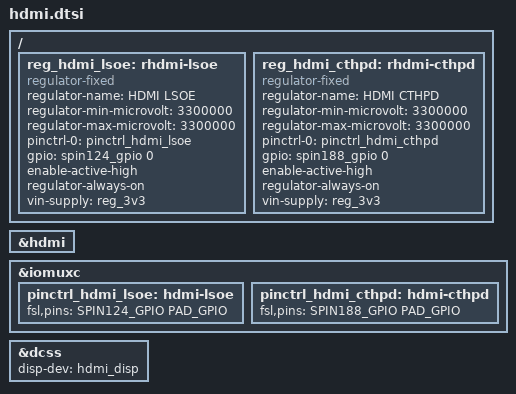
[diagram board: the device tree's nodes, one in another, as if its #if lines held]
/*
 * Copyright 2020 Keith & Koep GmbH
 *
 */

 /************************************************************************/

&hdmi {
	status = "okay";
};

&iomuxc {
	pinctrl_hdmi_lsoe: hdmi-lsoe 	{
		fsl,pins = < SPIN124_GPIO	PAD_GPIO >; 
	};
	pinctrl_hdmi_cthpd: hdmi-cthpd 	{
		fsl,pins = < SPIN188_GPIO	PAD_GPIO >; 
	};		
};

/ {
	reg_hdmi_lsoe: rhdmi-lsoe {
		compatible = "regulator-fixed";
		regulator-name = "HDMI LSOE";
		regulator-min-microvolt = <3300000>;
		regulator-max-microvolt = <3300000>;
		pinctrl-names = "default";
		pinctrl-0 = <&pinctrl_hdmi_lsoe>;
		gpio = <spin124_gpio 0>;
		enable-active-high;
		regulator-always-on;
		vin-supply = <&reg_3v3>;
	};
	reg_hdmi_cthpd: rhdmi-cthpd {
		compatible = "regulator-fixed";
		regulator-name = "HDMI CTHPD";
		regulator-min-microvolt = <3300000>;
		regulator-max-microvolt = <3300000>;
		pinctrl-names = "default";
		pinctrl-0 = <&pinctrl_hdmi_cthpd>;
		gpio = <spin188_gpio 0>;
		enable-active-high;
		regulator-always-on;
		vin-supply = <&reg_3v3>;
	};
};

#if defined (__DTS_TRIZEPS8_PINFUNC_H)
&dcss {
	status = "okay";
	disp-dev = "hdmi_disp";
};
#endif
/************************************************************************/
